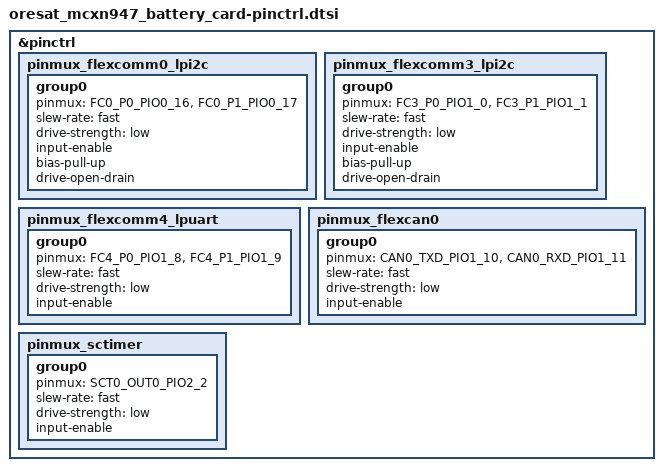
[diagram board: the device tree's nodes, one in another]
/*
 * Copyright 2024 NXP
 * SPDX-License-Identifier: Apache-2.0
 */


#include <nxp/mcx/MCXN947VDF-pinctrl.h>

&pinctrl {
	pinmux_flexcomm0_lpi2c: pinmux_flexcomm0_lpi2c {
		group0 {
			pinmux = <FC0_P0_PIO0_16>,
				<FC0_P1_PIO0_17>;
			slew-rate = "fast";
			drive-strength = "low";
			input-enable;
			bias-pull-up;
			drive-open-drain;
		};
	};

	pinmux_flexcomm3_lpi2c: pinmux_flexcomm3_lpi2c {
		group0 {
			pinmux = <FC3_P0_PIO1_0>,
				<FC3_P1_PIO1_1>;
			slew-rate = "fast";
			drive-strength = "low";
			input-enable;
			bias-pull-up;
			drive-open-drain;
		};
	};

	pinmux_flexcomm4_lpuart: pinmux_flexcomm4_lpuart {
		group0 {
			pinmux = <FC4_P0_PIO1_8>,
				<FC4_P1_PIO1_9>;
			slew-rate = "fast";
			drive-strength = "low";
			input-enable;
		};
	};

	pinmux_flexcan0: pinmux_flexcan0 {
		group0 {
			pinmux = <CAN0_TXD_PIO1_10>,
				<CAN0_RXD_PIO1_11>;
			slew-rate = "fast";
			drive-strength = "low";
			input-enable;
		};
	};

	pinmux_sctimer: pinmux_sctimer {
		group0 {
			pinmux = <SCT0_OUT0_PIO2_2>;
			slew-rate = "fast";
			drive-strength = "low";
			input-enable;
		};
	};
};
